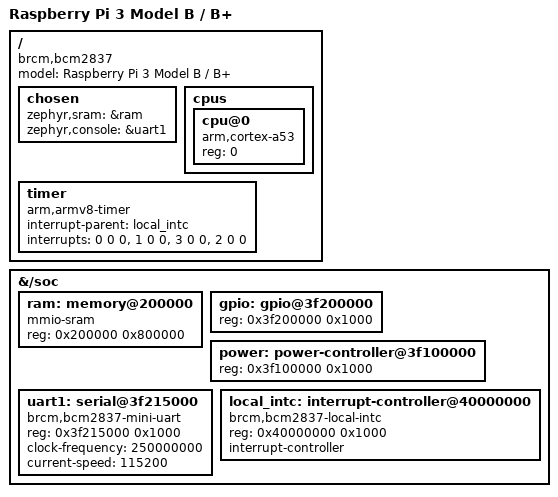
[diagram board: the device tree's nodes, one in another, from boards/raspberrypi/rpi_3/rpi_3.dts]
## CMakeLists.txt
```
cmake_minimum_required(VERSION 3.20.0)
list(APPEND BOARD_ROOT ${CMAKE_CURRENT_SOURCE_DIR})
list(APPEND SOC_ROOT ${CMAKE_CURRENT_SOURCE_DIR})
list(APPEND DTS_ROOT ${CMAKE_CURRENT_SOURCE_DIR})
set(RPIDUINO_SKETCH heartbeat CACHE STRING "RPiduino sketch to build")
if(RPIDUINO_SKETCH STREQUAL "uart_debug")
  list(APPEND EXTRA_CONF_FILE ${CMAKE_CURRENT_SOURCE_DIR}/sketches/uart_debug.conf)
  list(APPEND EXTRA_DTC_OVERLAY_FILE ${CMAKE_CURRENT_SOURCE_DIR}/sketches/uart_debug.overlay)
endif()
find_package(Zephyr REQUIRED HINTS $ENV{ZEPHYR_BASE})
project(rpiduino_zephyr LANGUAGES C CXX)

target_include_directories(app PRIVATE include)
if(RPIDUINO_SKETCH STREQUAL "gpio_loopback" OR RPIDUINO_SKETCH STREQUAL "uart_debug")
  if(NOT CONFIG_SOC_BCM2837)
    message(FATAL_ERROR "${RPIDUINO_SKETCH} requires the rpi_3 board")
  endif()
elseif(NOT RPIDUINO_SKETCH STREQUAL "heartbeat")
  message(FATAL_ERROR "RPIDUINO_SKETCH must be heartbeat, gpio_loopback, or uart_debug")
endif()
target_sources(app PRIVATE src/main.cpp sketches/${RPIDUINO_SKETCH}.cpp)
if(CONFIG_SOC_BCM2837)
  target_sources(app PRIVATE src/gpio_bcm2837.cpp src/uart_control.cpp)
endif()
if(RPIDUINO_SKETCH STREQUAL "uart_debug")
  target_sources(app PRIVATE drivers/sdhc/sdhc_bcm2835_sdhost.c src/image_update.cpp)
endif()
```

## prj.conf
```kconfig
CONFIG_CPP=y
CONFIG_SERIAL=y
CONFIG_CONSOLE=y
CONFIG_UART_CONSOLE=y
CONFIG_PRINTK=y
CONFIG_TIMEOUT_64BIT=y
```

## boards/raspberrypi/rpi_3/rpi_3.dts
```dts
/* SPDX-License-Identifier: Apache-2.0 */
/dts-v1/;

#include <arm64/armv8-a.dtsi>

/ {
	model = "Raspberry Pi 3 Model B / B+";
	compatible = "brcm,bcm2837";

	chosen {
		zephyr,sram = &ram;
		zephyr,console = &uart1;
	};

	cpus {
		#address-cells = <1>;
		#size-cells = <0>;

		cpu@0 {
			device_type = "cpu";
			compatible = "arm,cortex-a53";
			reg = <0>;
		};
	};

	timer {
		compatible = "arm,armv8-timer";
		interrupt-parent = <&local_intc>;
		/* Secure physical, non-secure physical, virtual, hypervisor. */
		interrupts = <0 0 0>, <1 0 0>, <3 0 0>, <2 0 0>;
	};
};

&{/soc} {
	ram: memory@200000 {
		compatible = "mmio-sram";
		device_type = "memory";
		reg = <0x200000 0x800000>;
	};

	gpio: gpio@3f200000 {
		reg = <0x3f200000 0x1000>;
	};

	power: power-controller@3f100000 {
		reg = <0x3f100000 0x1000>;
	};

	uart1: serial@3f215000 {
		compatible = "brcm,bcm2837-mini-uart";
		reg = <0x3f215000 0x1000>;
		clock-frequency = <250000000>;
		current-speed = <115200>;
	};

	local_intc: interrupt-controller@40000000 {
		compatible = "brcm,bcm2837-local-intc";
		reg = <0x40000000 0x1000>;
		interrupt-controller;
		#interrupt-cells = <3>;
	};
};
```

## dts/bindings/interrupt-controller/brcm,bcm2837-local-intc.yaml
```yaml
# SPDX-License-Identifier: Apache-2.0
description: Broadcom BCM2836/BCM2837 ARM-local interrupt controller
compatible: "brcm,bcm2837-local-intc"
include: base.yaml
interrupt-cells:
  - irq
  - priority
  - flags
```

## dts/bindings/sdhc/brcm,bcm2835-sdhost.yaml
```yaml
# Copyright (c) 2026 Jonathan Elliot Peace <jep@alphabetiq.com>
# SPDX-License-Identifier: Apache-2.0

description: |
  Broadcom BCM283x legacy SD Host Controller.

  Non-Arasan SD controller on the BCM283x SoCs, with a proprietary
  Broadcom register layout (SDCMD/SDARG/SDHSTS/SDEDM/SDDATA/SDCDIV
  at offsets 0x00..0x50), distinct from the Arasan SDHCI block on the
  same SoC.

compatible: "brcm,bcm2835-sdhost"

include: sdhc.yaml

properties:
  reg:
    required: true

  clock-frequency:
    type: int
    required: true
    description: |
      Frequency in Hz of the VPU core clock feeding the SDHost
      reference. The driver scales this down to the bus SD clock
      via SDCDIV.

  bus-width:
    type: int
    required: true
    description: |
      Number of data lines wired between the controller and the
      card: 1 or 4. The SDHost has no 8-bit mode.
```

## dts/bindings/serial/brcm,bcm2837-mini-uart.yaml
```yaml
# SPDX-License-Identifier: Apache-2.0
description: BCM2837 AUX mini-UART and auxiliary enable register
compatible: "brcm,bcm2837-mini-uart"
include: uart-controller.yaml
properties:
  reg:
    required: true
  clock-frequency:
    required: true
  current-speed:
    required: true
```

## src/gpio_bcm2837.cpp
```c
#include <rpiduino/gpio.hpp>

#include <errno.h>
#include <zephyr/devicetree.h>
#include <zephyr/irq.h>
#include <zephyr/kernel.h>
#include <zephyr/sys/sys_io.h>

namespace {
constexpr uintptr_t gpioBase = DT_REG_ADDR(DT_NODELABEL(gpio));
constexpr uintptr_t gpioSet = gpioBase + 0x1c;
constexpr uintptr_t gpioClear = gpioBase + 0x28;
constexpr uintptr_t gpioLevel = gpioBase + 0x34;
constexpr uintptr_t pullControl = gpioBase + 0x94;
constexpr uintptr_t pullClock = gpioBase + 0x98;

bool isHeaderGpio(unsigned int pin)
{
    return pin >= 2 && pin <= 27 && pin != 14 && pin != 15;
}
}

int pinMode(unsigned int pin, PinMode mode)
{
    if (!isHeaderGpio(pin)) {
        return -EINVAL;
    }

    uint32_t pull;
    switch (mode) {
    case INPUT:
    case OUTPUT:
        pull = 0;
        break;
    case INPUT_PULLDOWN:
        pull = 1;
        break;
    case INPUT_PULLUP:
        pull = 2;
        break;
    default:
        return -EINVAL;
    }

    const uintptr_t functionSelect = gpioBase + 4U * (pin / 10U);
    const unsigned int shift = 3U * (pin % 10U);
    const unsigned int key = irq_lock();
    const uint32_t function = mode == OUTPUT ? 1U : 0U;
    const uint32_t previous = sys_read32(functionSelect);
    if (mode == OUTPUT) {
        sys_write32(BIT(pin), gpioClear);
    }
    sys_write32((previous & ~(7U << shift)) | (function << shift), functionSelect);

    // BCM2837 latches the pull setting with the legacy GPPUD/GPPUDCLK sequence.
    sys_write32(pull, pullControl);
    k_busy_wait(5);
    sys_write32(BIT(pin), pullClock);
    k_busy_wait(5);
    sys_write32(0, pullControl);
    sys_write32(0, pullClock);
    irq_unlock(key);
    return 0;
}

int digitalWrite(unsigned int pin, PinValue value)
{
    if (!isHeaderGpio(pin) || (value != LOW && value != HIGH)) {
        return -EINVAL;
    }
    sys_write32(BIT(pin), value == HIGH ? gpioSet : gpioClear);
    return 0;
}

int digitalRead(unsigned int pin)
{
    if (!isHeaderGpio(pin)) {
        return -EINVAL;
    }
    return (sys_read32(gpioLevel) & BIT(pin)) != 0 ? HIGH : LOW;
}
```

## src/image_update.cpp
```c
#include <rpiduino/image_update.hpp>

#include <errno.h>
#include <ff.h>
#include <zephyr/fs/fs.h>
#include <zephyr/sys/crc.h>
#include <zephyr/sys/printk.h>

namespace {
constexpr char mountPoint[] = "/SD:";
constexpr char imageTemp[] = "/SD:/RPITMP.IMG";
constexpr char selectorTemp[] = "/SD:/RPINEXT.TMP";
constexpr char selector[] = "/SD:/RPINEXT.TXT";
FATFS fat;
fs_mount_t sdMount = {
    .type = FS_FATFS,
    .mnt_point = mountPoint,
    .fs_data = &fat,
    .flags = FS_MOUNT_FLAG_NO_FORMAT | FS_MOUNT_FLAG_USE_DISK_ACCESS,
};
bool mounted;

int mount()
{
    if (mounted) {
        return 0;
    }
    const int result = fs_mount(&sdMount);
    mounted = result == 0;
    return result;
}

int verifyImage(const char *path, size_t size, uint32_t checksum)
{
    fs_file_t file;
    fs_file_t_init(&file);
    int result = fs_open(&file, path, FS_O_READ);
    if (result < 0) {
        return result;
    }
    uint8_t buffer[512];
    uint32_t crc = 0;
    size_t total = 0;
    while (true) {
        const ssize_t count = fs_read(&file, buffer, sizeof(buffer));
        if (count <= 0) {
            result = static_cast<int>(count);
            break;
        }
        total += static_cast<size_t>(count);
        if (total > size) {
            result = -EBADMSG;
            break;
        }
        crc = crc32_ieee_update(crc, buffer, static_cast<size_t>(count));
    }
    const int closed = fs_close(&file);
    if (result < 0) {
        return result;
    }
    if (closed < 0) {
        return closed;
    }
    return total == size && crc == checksum ? 0 : -EBADMSG;
}

int writeFile(const char *path, const void *bytes, size_t size)
{
    fs_file_t file;
    fs_file_t_init(&file);
    int result = fs_open(&file, path, FS_O_CREATE | FS_O_WRITE | FS_O_TRUNC);
    if (result < 0) {
        return result;
    }
    const ssize_t count = fs_write(&file, bytes, size);
    result = count < 0 ? static_cast<int>(count)
                       : static_cast<size_t>(count) == size ? fs_sync(&file) : -ENOSPC;
    const int closed = fs_close(&file);
    return result < 0 ? result : closed;
}

void imagePath(char (&path)[18], uint32_t crc)
{
    snprintk(path, sizeof(path), "%s/%08X.IMG", mountPoint, static_cast<unsigned int>(crc));
}
}

int saveImage(const uint8_t *image, size_t size, uint32_t crc)
{
    int result = mount();
    if (result < 0) {
        return result;
    }
    char path[18];
    imagePath(path, crc);
    result = verifyImage(path, size, crc);
    if (result != -ENOENT) {
        return result;
    }
    result = writeFile(imageTemp, image, size);
    if (result == 0) {
        result = verifyImage(imageTemp, size, crc);
    }
    if (result == 0) {
        result = fs_rename(imageTemp, path);
    }
    if (result < 0) {
        fs_unlink(imageTemp);
    }
    return result;
}

int selectImage(size_t size, uint32_t crc)
{
    char path[18];
    imagePath(path, crc);
    int result = mount();
    if (result == 0) {
        result = verifyImage(path, size, crc);
    }
    if (result < 0) {
        return result;
    }
    char config[32];
    const int length = snprintk(config, sizeof(config), "kernel=%08X.IMG\n",
                                static_cast<unsigned int>(crc));
    result = writeFile(selectorTemp, config, static_cast<size_t>(length));
    if (result == 0) {
        result = fs_rename(selectorTemp, selector);
    }
    if (result < 0) {
        fs_unlink(selectorTemp);
    }
    return result;
}

int clearImageSelection()
{
    const int mountedResult = mount();
    if (mountedResult < 0) {
        return mountedResult;
    }
    const int result = fs_unlink(selector);
    return result == -ENOENT ? 0 : result;
}
```

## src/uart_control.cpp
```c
#include <rpiduino/uart_control.hpp>
#include <rpiduino/sketch.hpp>
#include <string.h>
#include <zephyr/device.h>
#include <zephyr/devicetree.h>
#include <zephyr/drivers/uart.h>
#include <zephyr/sys/printk.h>
#include <zephyr/sys/reboot.h>

namespace {
const device *const console = DEVICE_DT_GET(DT_CHOSEN(zephyr_console));
char line[32];
size_t length;
bool overflow;
unsigned char received;
}

[[noreturn]] void rebootFromUart()
{
    printk("@RPIDUINO RESETTING\n");
    // Let the UART finish transmitting before resetting its clock.
    delay(50);
    sys_reboot(SYS_REBOOT_COLD);
}

void pollUartControl()
{
    while (uart_poll_in(console, &received) == 0) {
        if (received == '\n') {
            if (!overflow) {
                line[length] = '\0';
                if (strcmp(line, "@RPIDUINO RESET") == 0) {
                    rebootFromUart();
                } else if (strcmp(line, "@RPIDUINO PING") == 0) {
                    printk("@RPIDUINO READY 1\n");
                } else if (strcmp(line, "@RPIDUINO DEBUG") == 0) {
                    printk("@RPIDUINO DEBUG board=%s uptime_ms=%u img=unsupported\n",
                           CONFIG_BOARD_TARGET, static_cast<unsigned int>(millis()));
                }
            }
            length = 0;
            overflow = false;
        } else if (received != '\r') {
            if (length < sizeof(line) - 1 && received >= 32 && received <= 126) {
                line[length++] = static_cast<char>(received);
            } else {
                overflow = true;
            }
        }
    }
}
```
